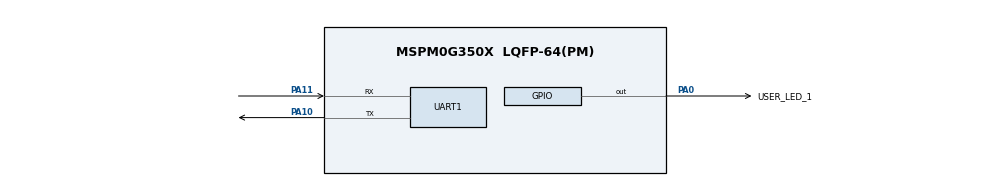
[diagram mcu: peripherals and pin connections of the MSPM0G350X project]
/**
 * @cliArgs --device "MSPM0G350X" --part "Default" --package "LQFP-64(PM)" --product "mspm0_sdk@2.10.00.04"
 * @versions {"tool":"1.26.2+4477"}
 */

/**
 * Import the modules used in this configuration.
 */
const GPIO   = scripting.addModule("/ti/driverlib/GPIO", {}, false);
const GPIO1  = GPIO.addInstance();
const SYSCTL = scripting.addModule("/ti/driverlib/SYSCTL");
const UART   = scripting.addModule("/ti/driverlib/UART", {}, false);
const UART1  = UART.addInstance();

/**
 * Write custom configuration values to the imported modules.
 */
GPIO1.$name                              = "GPIO_LEDS";
GPIO1.associatedPins.create(4);
GPIO1.associatedPins[0].$name            = "USER_LED_1";
GPIO1.associatedPins[0].assignedPort     = "PORTA";
GPIO1.associatedPins[0].initialValue     = "SET";
GPIO1.associatedPins[0].assignedPin      = "0";
GPIO1.associatedPins[0].pin.$assign      = "PA0";
GPIO1.associatedPins[1].$name            = "USER_TEST";
GPIO1.associatedPins[1].assignedPort     = "PORTA";
GPIO1.associatedPins[1].assignedPin      = "15";
GPIO1.associatedPins[1].initialValue     = "SET";
GPIO1.associatedPins[2].$name            = "BUTTON";
GPIO1.associatedPins[2].direction        = "INPUT";
GPIO1.associatedPins[2].assignedPort     = "PORTA";
GPIO1.associatedPins[2].ioStructure      = "HS";
GPIO1.associatedPins[2].assignedPin      = "13";
GPIO1.associatedPins[2].internalResistor = "PULL_DOWN";
GPIO1.associatedPins[3].$name            = "LED_STRIP";
GPIO1.associatedPins[3].ioStructure      = "SD";
GPIO1.associatedPins[3].assignedPort     = "PORTA";
GPIO1.associatedPins[3].assignedPin      = "27";

const Board           = scripting.addModule("/ti/driverlib/Board", {}, false);
Board.configureUnused = true;

SYSCTL.powerPolicy = "STANDBY0";
SYSCTL.clockTreeEn = true;

UART1.$name                    = "UART_0";
UART1.rxFifoThreshold          = "DL_UART_RX_FIFO_LEVEL_ONE_ENTRY";
UART1.enableDMARX              = false;
UART1.enableDMATX              = false;
UART1.enabledInterrupts        = ["RX"];
UART1.targetBaudRate           = 115200;
UART1.peripheral.$assign       = "UART0";
UART1.peripheral.rxPin.$assign = "PA11";
UART1.peripheral.txPin.$assign = "PA10";
UART1.txPinConfig.$name        = "ti_driverlib_gpio_GPIOPinGeneric0";
UART1.rxPinConfig.$name        = "ti_driverlib_gpio_GPIOPinGeneric1";

/**
 * Pinmux solution for unlocked pins/peripherals. This ensures that minor changes to the automatic solver in a future
 * version of the tool will not impact the pinmux you originally saw.  These lines can be completely deleted in order to
 * re-solve from scratch.
 */
GPIO1.associatedPins[1].pin.$suggestSolution = "PA15";
GPIO1.associatedPins[2].pin.$suggestSolution = "PA13";
GPIO1.associatedPins[3].pin.$suggestSolution = "PA27";
Board.peripheral.$suggestSolution            = "DEBUGSS";
Board.peripheral.swclkPin.$suggestSolution   = "PA20";
Board.peripheral.swdioPin.$suggestSolution   = "PA19";
